# ESP32-S3 register map
Vendor: ESPRESSIF SYSTEMS (SHANGHAI) CO., LTD.; Series: ESP32 S-Series; File version: 22
CPU: Xtensa LX7 r0p0, little endian, no MPU, FPU, 0 interrupt priority bits
Address unit: 32 bits
Registers are 32-bit, read-write, reset 0x0 unless marked. A register's access mark holds for its fields unless they carry their own. Offsets are from the block's base; [hi:lo] are bit positions; {n}, {i} and the like mark numbered series; <NAME> marks a mode.

## I2S1 — I2S (Inter-IC Sound) Controller 1
Base 0x6002D000
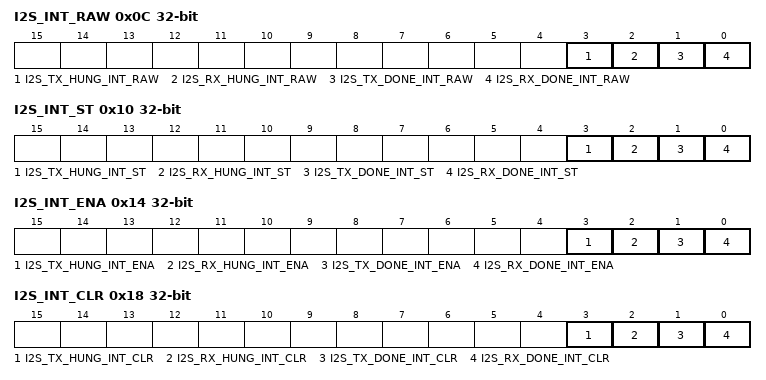
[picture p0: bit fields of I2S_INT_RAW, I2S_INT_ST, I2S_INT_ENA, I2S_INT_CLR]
0x0C I2S_INT_RAW ro — I2S interrupt raw register, valid in level.
  [3] I2S_TX_HUNG_INT_RAW — The raw interrupt status bit for the i2s_tx_hung_int interrupt
  [2] I2S_RX_HUNG_INT_RAW — The raw interrupt status bit for the i2s_rx_hung_int interrupt
  [1] I2S_TX_DONE_INT_RAW — The raw interrupt status bit for the i2s_tx_done_int interrupt
  [0] I2S_RX_DONE_INT_RAW — The raw interrupt status bit for the i2s_rx_done_int interrupt
0x10 I2S_INT_ST ro — I2S interrupt status register.
  [3] I2S_TX_HUNG_INT_ST — The masked interrupt status bit for the i2s_tx_hung_int interrupt
  [2] I2S_RX_HUNG_INT_ST — The masked interrupt status bit for the i2s_rx_hung_int interrupt
  [1] I2S_TX_DONE_INT_ST — The masked interrupt status bit for the i2s_tx_done_int interrupt
  [0] I2S_RX_DONE_INT_ST — The masked interrupt status bit for the i2s_rx_done_int interrupt
0x14 I2S_INT_ENA — I2S interrupt enable register.
  [3] I2S_TX_HUNG_INT_ENA — The interrupt enable bit for the i2s_tx_hung_int interrupt
  [2] I2S_RX_HUNG_INT_ENA — The interrupt enable bit for the i2s_rx_hung_int interrupt
  [1] I2S_TX_DONE_INT_ENA — The interrupt enable bit for the i2s_tx_done_int interrupt
  [0] I2S_RX_DONE_INT_ENA — The interrupt enable bit for the i2s_rx_done_int interrupt
0x18 I2S_INT_CLR wo — I2S interrupt clear register.
  [3] I2S_TX_HUNG_INT_CLR — Set this bit to clear the i2s_tx_hung_int interrupt
  [2] I2S_RX_HUNG_INT_CLR — Set this bit to clear the i2s_rx_hung_int interrupt
  [1] I2S_TX_DONE_INT_CLR — Set this bit to clear the i2s_tx_done_int interrupt
  [0] I2S_RX_DONE_INT_CLR — Set this bit to clear the i2s_rx_done_int interrupt
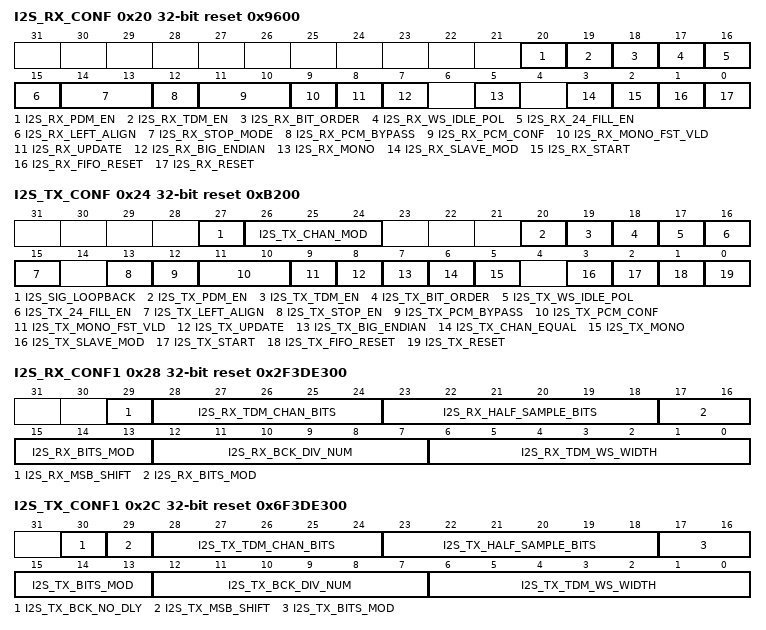
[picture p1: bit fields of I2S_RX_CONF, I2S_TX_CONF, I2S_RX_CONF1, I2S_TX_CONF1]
0x20 I2S_RX_CONF access per field reset 0x9600 — I2S RX configure register
  [20] I2S_RX_PDM_EN rw — 1: Enable I2S PDM Rx mode . 0: Disable.
  [19] I2S_RX_TDM_EN rw — 1: Enable I2S TDM Rx mode . 0: Disable.
  [18] I2S_RX_BIT_ORDER rw — I2S Rx bit endian. 1:small endian, the LSB is received first. 0:big endian, the MSB is received first.
  [17] I2S_RX_WS_IDLE_POL rw — 0: WS should be 0 when receiving left channel data, and WS is 1in right channel. 1: WS should be 1 when receiving left channel data, and WS is 0in right channel.
  [16] I2S_RX_24_FILL_EN rw — 1: store 24 channel bits to 32 bits. 0:store 24 channel bits to 24 bits.
  [15] I2S_RX_LEFT_ALIGN rw — 1: I2S RX left alignment mode. 0: I2S RX right alignment mode.
  [14:13] I2S_RX_STOP_MODE rw — 0 : I2S Rx only stop when reg_rx_start is cleared. 1: Stop when reg_rx_start is 0 or in_suc_eof is 1. 2: Stop I2S RX when reg_rx_start is 0 or RX FIFO is full.
  [12] I2S_RX_PCM_BYPASS rw — Set this bit to bypass Compress/Decompress module for received data.
  [11:10] I2S_RX_PCM_CONF rw — I2S RX compress/decompress configuration bit. & 0 (atol): A-Law decompress, 1 (ltoa) : A-Law compress, 2 (utol) : u-Law decompress, 3 (ltou) : u-Law compress. &
  [9] I2S_RX_MONO_FST_VLD rw — 1: The first channel data value is valid in I2S RX mono mode. 0: The second channel data value is valid in I2S RX mono mode.
  [8] I2S_RX_UPDATE rw — Set 1 to update I2S RX registers from APB clock domain to I2S RX clock domain. This bit will be cleared by hardware after update register done.
  [7] I2S_RX_BIG_ENDIAN rw — I2S Rx byte endian, 1: low addr value to high addr. 0: low addr with low addr value.
  [5] I2S_RX_MONO rw — Set this bit to enable receiver in mono mode
  [3] I2S_RX_SLAVE_MOD rw — Set this bit to enable slave receiver mode
  [2] I2S_RX_START rw — Set this bit to start receiving data
  [1] I2S_RX_FIFO_RESET wo — Set this bit to reset Rx AFIFO
  [0] I2S_RX_RESET wo — Set this bit to reset receiver
0x24 I2S_TX_CONF access per field reset 0xB200 — I2S TX configure register
  [27] I2S_SIG_LOOPBACK rw — Enable signal loop back mode with transmitter module and receiver module sharing the same WS and BCK signals.
  [26:24] I2S_TX_CHAN_MOD rw — I2S transmitter channel mode configuration bits.
  [20] I2S_TX_PDM_EN rw — 1: Enable I2S PDM Tx mode . 0: Disable.
  [19] I2S_TX_TDM_EN rw — 1: Enable I2S TDM Tx mode . 0: Disable.
  [18] I2S_TX_BIT_ORDER rw — I2S Tx bit endian. 1:small endian, the LSB is sent first. 0:big endian, the MSB is sent first.
  [17] I2S_TX_WS_IDLE_POL rw — 0: WS should be 0 when sending left channel data, and WS is 1in right channel. 1: WS should be 1 when sending left channel data, and WS is 0in right channel.
  [16] I2S_TX_24_FILL_EN rw — 1: Sent 32 bits in 24 channel bits mode. 0: Sent 24 bits in 24 channel bits mode
  [15] I2S_TX_LEFT_ALIGN rw — 1: I2S TX left alignment mode. 0: I2S TX right alignment mode.
  [13] I2S_TX_STOP_EN rw — Set this bit to stop disable output BCK signal and WS signal when tx FIFO is emtpy
  [12] I2S_TX_PCM_BYPASS rw — Set this bit to bypass Compress/Decompress module for transmitted data.
  [11:10] I2S_TX_PCM_CONF rw — I2S TX compress/decompress configuration bit. & 0 (atol): A-Law decompress, 1 (ltoa) : A-Law compress, 2 (utol) : u-Law decompress, 3 (ltou) : u-Law compress. &
  [9] I2S_TX_MONO_FST_VLD rw — 1: The first channel data value is valid in I2S TX mono mode. 0: The second channel data value is valid in I2S TX mono mode.
  [8] I2S_TX_UPDATE rw — Set 1 to update I2S TX registers from APB clock domain to I2S TX clock domain. This bit will be cleared by hardware after update register done.
  [7] I2S_TX_BIG_ENDIAN rw — I2S Tx byte endian, 1: low addr value to high addr. 0: low addr with low addr value.
  [6] I2S_TX_CHAN_EQUAL rw — 1: The value of Left channel data is equal to the value of right channel data in I2S TX mono mode or TDM channel select mode. 0: The invalid channel data is reg_i2s_single_data in I2S TX mono mode or TDM channel select mode.
  [5] I2S_TX_MONO rw — Set this bit to enable transmitter in mono mode
  [3] I2S_TX_SLAVE_MOD rw — Set this bit to enable slave transmitter mode
  [2] I2S_TX_START rw — Set this bit to start transmitting data
  [1] I2S_TX_FIFO_RESET wo — Set this bit to reset Tx AFIFO
  [0] I2S_TX_RESET wo — Set this bit to reset transmitter
0x28 I2S_RX_CONF1 reset 0x2F3DE300 — I2S RX configure register 1
  [29] I2S_RX_MSB_SHIFT — Set this bit to enable receiver in Phillips standard mode
  [28:24] I2S_RX_TDM_CHAN_BITS — The Rx bit number for each channel minus 1in TDM mode.
  [23:18] I2S_RX_HALF_SAMPLE_BITS — I2S Rx half sample bits -1.
  [17:13] I2S_RX_BITS_MOD — Set the bits to configure the valid data bit length of I2S receiver channel. 7: all the valid channel data is in 8-bit-mode. 15: all the valid channel data is in 16-bit-mode. 23: all the valid channel data is in 24-bit-mode. 31:all the valid channel data is in 32-bit-mode.
  [12:7] I2S_RX_BCK_DIV_NUM — Bit clock configuration bits in receiver mode.
  [6:0] I2S_RX_TDM_WS_WIDTH — The width of rx_ws_out in TDM mode is (I2S_RX_TDM_WS_WIDTH[6:0] +1) * T_bck
0x2C I2S_TX_CONF1 reset 0x6F3DE300 — I2S TX configure register 1
  [30] I2S_TX_BCK_NO_DLY — 1: BCK is not delayed to generate pos/neg edge in master mode. 0: BCK is delayed to generate pos/neg edge in master mode.
  [29] I2S_TX_MSB_SHIFT — Set this bit to enable transmitter in Phillips standard mode
  [28:24] I2S_TX_TDM_CHAN_BITS — The Tx bit number for each channel minus 1in TDM mode.
  [23:18] I2S_TX_HALF_SAMPLE_BITS — I2S Tx half sample bits -1.
  [17:13] I2S_TX_BITS_MOD — Set the bits to configure the valid data bit length of I2S transmitter channel. 7: all the valid channel data is in 8-bit-mode. 15: all the valid channel data is in 16-bit-mode. 23: all the valid channel data is in 24-bit-mode. 31:all the valid channel data is in 32-bit-mode.
  [12:7] I2S_TX_BCK_DIV_NUM — Bit clock configuration bits in transmitter mode.
  [6:0] I2S_TX_TDM_WS_WIDTH — The width of tx_ws_out in TDM mode is (I2S_TX_TDM_WS_WIDTH[6:0] +1) * T_bck
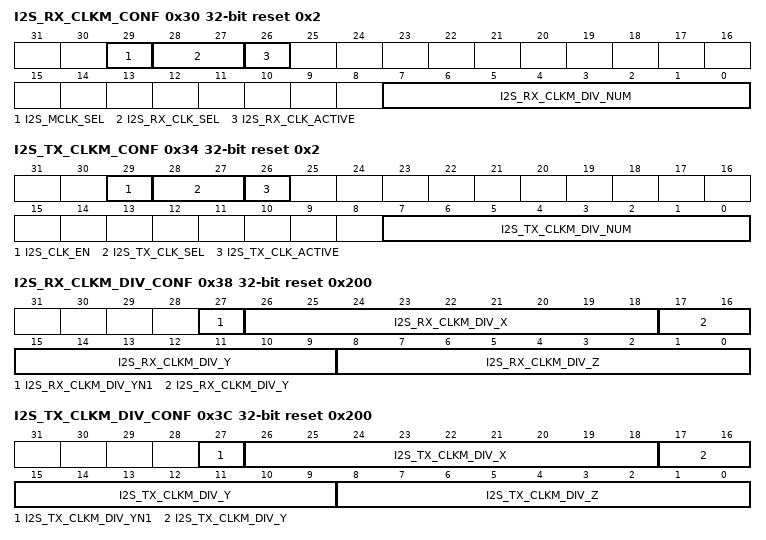
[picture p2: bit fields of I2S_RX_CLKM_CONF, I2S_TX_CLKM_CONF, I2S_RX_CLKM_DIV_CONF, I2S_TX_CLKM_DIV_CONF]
0x30 I2S_RX_CLKM_CONF reset 0x2 — I2S RX clock configure register
  [29] I2S_MCLK_SEL — 0: UseI2S Tx module clock as I2S_MCLK_OUT. 1: UseI2S Rx module clock as I2S_MCLK_OUT.
  [28:27] I2S_RX_CLK_SEL — Select I2S Rx module source clock. 0: no clock. 1: APLL. 2: CLK160. 3: I2S_MCLK_in.
  [26] I2S_RX_CLK_ACTIVE — I2S Rx module clock enable signal.
  [7:0] I2S_RX_CLKM_DIV_NUM — Integral I2S clock divider value
0x34 I2S_TX_CLKM_CONF reset 0x2 — I2S TX clock configure register
  [29] I2S_CLK_EN — Set this bit to enable clk gate
  [28:27] I2S_TX_CLK_SEL — Select I2S Tx module source clock. 0: XTAL clock. 1: APLL. 2: CLK160. 3: I2S_MCLK_in.
  [26] I2S_TX_CLK_ACTIVE — I2S Tx module clock enable signal.
  [7:0] I2S_TX_CLKM_DIV_NUM — Integral I2S TX clock divider value. f_I2S_CLK = f_I2S_CLK_S/(N+b/a). There will be (a-b) * n-div and b * (n+1)-div. So the average combination will be: for b <= a/2, z * [x * n-div + (n+1)-div] + y * n-div. For b > a/2, z * [n-div + x * (n+1)-div] + y * (n+1)-div.
0x38 I2S_RX_CLKM_DIV_CONF reset 0x200 — I2S RX module clock divider configure register
  [27] I2S_RX_CLKM_DIV_YN1 — For b <= a/2, the value of I2S_RX_CLKM_DIV_YN1 is 0 . For b > a/2, the value of I2S_RX_CLKM_DIV_YN1 is 1.
  [26:18] I2S_RX_CLKM_DIV_X — For b <= a/2, the value of I2S_RX_CLKM_DIV_X is (a/b) - 1. For b > a/2, the value of I2S_RX_CLKM_DIV_X is (a/(a-b)) - 1.
  [17:9] I2S_RX_CLKM_DIV_Y — For b <= a/2, the value of I2S_RX_CLKM_DIV_Y is (a%b) . For b > a/2, the value of I2S_RX_CLKM_DIV_Y is (a%(a-b)).
  [8:0] I2S_RX_CLKM_DIV_Z — For b <= a/2, the value of I2S_RX_CLKM_DIV_Z is b. For b > a/2, the value of I2S_RX_CLKM_DIV_Z is (a-b).
0x3C I2S_TX_CLKM_DIV_CONF reset 0x200 — I2S TX module clock divider configure register
  [27] I2S_TX_CLKM_DIV_YN1 — For b <= a/2, the value of I2S_TX_CLKM_DIV_YN1 is 0 . For b > a/2, the value of I2S_TX_CLKM_DIV_YN1 is 1.
  [26:18] I2S_TX_CLKM_DIV_X — For b <= a/2, the value of I2S_TX_CLKM_DIV_X is (a/b) - 1. For b > a/2, the value of I2S_TX_CLKM_DIV_X is (a/(a-b)) - 1.
  [17:9] I2S_TX_CLKM_DIV_Y — For b <= a/2, the value of I2S_TX_CLKM_DIV_Y is (a%b) . For b > a/2, the value of I2S_TX_CLKM_DIV_Y is (a%(a-b)).
  [8:0] I2S_TX_CLKM_DIV_Z — For b <= a/2, the value of I2S_TX_CLKM_DIV_Z is b. For b > a/2, the value of I2S_TX_CLKM_DIV_Z is (a-b).
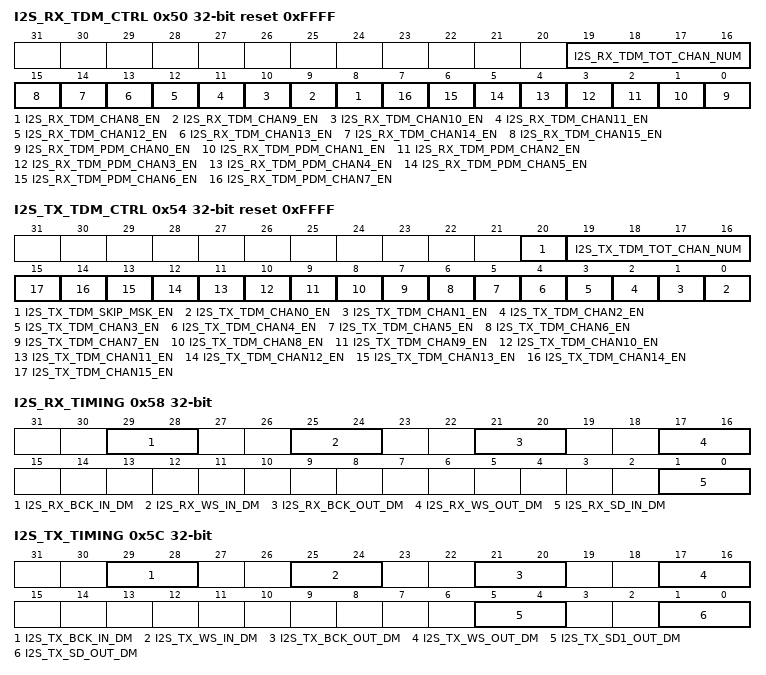
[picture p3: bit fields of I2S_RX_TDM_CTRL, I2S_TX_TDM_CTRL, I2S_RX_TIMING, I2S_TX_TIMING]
0x50 I2S_RX_TDM_CTRL reset 0xFFFF — I2S TX TDM mode control register
  [19:16] I2S_RX_TDM_TOT_CHAN_NUM — The total channel number of I2S TX TDM mode.
  [n] I2S_RX_TDM_CHAN{n}_EN (n=8..15) — 1: Enable the valid data input of I2S RX TDM channel {n}. 0: Disable, just input 0 in this channel.
  [n] I2S_RX_TDM_PDM_CHAN{n}_EN (n=0..7) — 1: Enable the valid data input of I2S RX TDM or PDM channel {n}. 0: Disable, just input 0 in this channel.
0x54 I2S_TX_TDM_CTRL reset 0xFFFF — I2S TX TDM mode control register
  [20] I2S_TX_TDM_SKIP_MSK_EN — When DMA TX buffer stores the data of (REG_TX_TDM_TOT_CHAN_NUM + 1) channels, and only the data of the enabled channels is sent, then this bit should be set. Clear it when all the data stored in DMA TX buffer is for enabled channels.
  [19:16] I2S_TX_TDM_TOT_CHAN_NUM — The total channel number of I2S TX TDM mode.
  [n] I2S_TX_TDM_CHAN{n}_EN (n=0..15) — 1: Enable the valid data output of I2S TX TDM channel {n}. 0: Disable, just output 0 in this channel.
0x58 I2S_RX_TIMING — I2S RX timing control register
  [29:28] I2S_RX_BCK_IN_DM — The delay mode of I2S Rx BCK input signal. 0: bypass. 1: delay by pos edge. 2: delay by neg edge. 3: not used.
  [25:24] I2S_RX_WS_IN_DM — The delay mode of I2S Rx WS input signal. 0: bypass. 1: delay by pos edge. 2: delay by neg edge. 3: not used.
  [21:20] I2S_RX_BCK_OUT_DM — The delay mode of I2S Rx BCK output signal. 0: bypass. 1: delay by pos edge. 2: delay by neg edge. 3: not used.
  [17:16] I2S_RX_WS_OUT_DM — The delay mode of I2S Rx WS output signal. 0: bypass. 1: delay by pos edge. 2: delay by neg edge. 3: not used.
  [1:0] I2S_RX_SD_IN_DM — The delay mode of I2S Rx SD input signal. 0: bypass. 1: delay by pos edge. 2: delay by neg edge. 3: not used.
0x5C I2S_TX_TIMING — I2S TX timing control register
  [29:28] I2S_TX_BCK_IN_DM — The delay mode of I2S TX BCK input signal. 0: bypass. 1: delay by pos edge. 2: delay by neg edge. 3: not used.
  [25:24] I2S_TX_WS_IN_DM — The delay mode of I2S TX WS input signal. 0: bypass. 1: delay by pos edge. 2: delay by neg edge. 3: not used.
  [21:20] I2S_TX_BCK_OUT_DM — The delay mode of I2S TX BCK output signal. 0: bypass. 1: delay by pos edge. 2: delay by neg edge. 3: not used.
  [17:16] I2S_TX_WS_OUT_DM — The delay mode of I2S TX WS output signal. 0: bypass. 1: delay by pos edge. 2: delay by neg edge. 3: not used.
  [5:4] I2S_TX_SD1_OUT_DM — The delay mode of I2S TX SD1 output signal. 0: bypass. 1: delay by pos edge. 2: delay by neg edge. 3: not used.
  [1:0] I2S_TX_SD_OUT_DM — The delay mode of I2S TX SD output signal. 0: bypass. 1: delay by pos edge. 2: delay by neg edge. 3: not used.
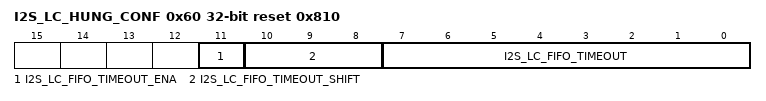
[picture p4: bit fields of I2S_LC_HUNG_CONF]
0x60 I2S_LC_HUNG_CONF reset 0x810 — I2S HUNG configure register.
  [11] I2S_LC_FIFO_TIMEOUT_ENA — The enable bit for FIFO timeout
  [10:8] I2S_LC_FIFO_TIMEOUT_SHIFT — The bits are used to scale tick counter threshold. The tick counter is reset when counter value >= 88000/2^i2s_lc_fifo_timeout_shift
  [7:0] I2S_LC_FIFO_TIMEOUT — the i2s_tx_hung_int interrupt or the i2s_rx_hung_int interrupt will be triggered when fifo hung counter is equal to this value
0x64 I2S_RXEOF_NUM reset 0x40 — I2S RX data number control register.
  [11:0] I2S_RX_EOF_NUM — The receive data bit length is (I2S_RX_BITS_MOD[4:0] + 1) * (REG_RX_EOF_NUM[11:0] + 1) . It will trigger in_suc_eof interrupt in the configured DMA RX channel.
0x68 I2S_CONF_SIGLE_DATA — I2S signal data register
  [31:0] I2S_SINGLE_DATA — The configured constant channel data to be sent out.
0x6C I2S_STATE ro reset 0x1 — I2S TX status register
  [0] I2S_TX_IDLE — 1: i2s_tx is idle state. 0: i2s_tx is working.
0x80 I2S_DATE reset 0x2009070 — Version control register
  [27:0] I2S_DATE — I2S version control register
